VERSION ""

NS_ :

BS_: 500

BU_: Vector__XXX

BO_ 330 MSG_14A: 8 Vector__XXX
 SG_ Steering_Angle : 48|16@0- (0.1,0) [-600|600] "��" Vector__XXX

BO_ 380 MSG_17C: 8 Vector__XXX
 SG_ Brake_Light : 24|1@0+ (1,0) [0|1] "on/off" Vector__XXX
 SG_ Engine_Speed : 32|16@0+ (1,0) [0|10000] "rpm" Vector__XXX
 SG_ Accelerator_Pedal_Position : 56|8@0+ (0.392157,0) [0|100] "%" Vector__XXX

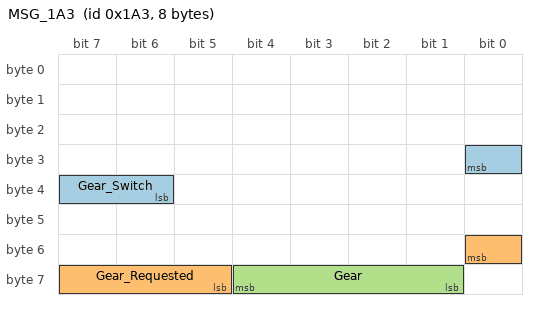
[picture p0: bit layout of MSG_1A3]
BO_ 419 MSG_1A3: 8 Vector__XXX
 SG_ Gear_Switch : 24|3@0+ (1,0) [0|7] "" Vector__XXX
 SG_ Gear_Requested : 48|4@0+ (1,0) [0|15] "" Vector__XXX
 SG_ Gear : 60|4@0+ (1,0) [0|14] "" Vector__XXX

BO_ 420 MSG_1A4: 8 Vector__XXX
 SG_ Brake_Position : 48|10@0+ (0.142857,-14.57) [0|100] "%" Vector__XXX

BO_ 597 MSG_255: 8 Vector__XXX
 SG_ Wheel_Speed_RR_kph : 32|8@0+ (1,0) [0|400] "km/h" Vector__XXX
 SG_ Wheel_Speed_RR_kph : 32|8@0+ (1.00040731,0) [0|644] "km/h" Vector__XXX
 SG_ Wheel_Speed_RR_mph : 32|8@0+ (0.621371,0) [0|400] "mph" Vector__XXX
 SG_ Wheel_Speed_RR_mph : 32|8@0+ (0.621,0) [0|248.4] "mph" Vector__XXX
 SG_ Wheel_Speed_RL_kph : 40|8@0+ (1,0) [0|400] "km/h" Vector__XXX
 SG_ Wheel_Speed_RL_kph : 40|8@0+ (1.00040731,0) [0|644] "km/h" Vector__XXX
 SG_ Wheel_Speed_RL_mph : 40|8@0+ (0.621371,0) [0|400] "mph" Vector__XXX
 SG_ Wheel_Speed_RL_mph : 40|8@0+ (0.621,0) [0|248.4] "mph" Vector__XXX
 SG_ Wheel_Speed_FR_kph : 48|8@0+ (1,0) [0|400] "km/h" Vector__XXX
 SG_ Wheel_Speed_FR_kph : 48|8@0+ (1.00040731,0) [0|644] "km/h" Vector__XXX
 SG_ Wheel_Speed_FR_mph : 48|8@0+ (0.621371,0) [0|400] "mph" Vector__XXX
 SG_ Wheel_Speed_FR_mph : 48|8@0+ (0.621,0) [0|248.4] "mph" Vector__XXX
 SG_ Wheel_Speed_FL_kph : 56|8@0+ (1,0) [0|400] "km/h" Vector__XXX
 SG_ Wheel_Speed_FL_kph : 56|8@0+ (1.00040731,0) [0|644] "km/h" Vector__XXX
 SG_ Wheel_Speed_FL_mph : 56|8@0+ (0.621371,0) [0|400] "mph" Vector__XXX
 SG_ Wheel_Speed_FL_mph : 56|8@0+ (0.621,0) [0|248.4] "mph" Vector__XXX

BO_ 777 MSG_309: 8 Vector__XXX
 SG_ Indicated_Vehicle_Speed_kph : 48|16@0+ (0.01,0) [0|500] "km/h" Vector__XXX
 SG_ Indicated_Vehicle_Speed_mph : 48|16@0+ (0.00621,0) [0|310.5] "mph" Vector__XXX

BO_ 891 MSG_37B: 8 Vector__XXX
 SG_ Full_Beam : 26|1@0+ (1,0) [0|1] "" Vector__XXX
 SG_ Headlights : 27|2@0+ (1,0) [0|3] "" Vector__XXX
